AUTOSAR XML (schema 00048)
package /MICROSAR/vDem42_swc/DataTypes
  12 x impl type:
    Dem_DTCFormatType: compu {0=DEM_DTC_FORMAT_OBD, 1=DEM_DTC_FORMAT_UDS, 2=DEM_DTC_FORMAT_J1939}, range raw 0..255, implementation-data-type=uint8
    Dem_DTCOriginType:
      compu {1=DEM_DTC_ORIGIN_PRIMARY_MEMORY, 2=DEM_DTC_ORIGIN_MIRROR_MEMORY, 3=DEM_DTC_ORIGIN_PERMANENT_MEMORY, 4=DEM_DTC_ORIGIN_OBD_RELEVANT_MEMORY, 5=DEM_DTC_ORIGIN_SECONDARY_MEMORY, 5=DEM_DTC_ORIGIN_USERDEFINED_MEMORY_10, 5=DEM_DTC_ORIGIN_USERDEFINED_MEMORY_11, 5=DEM_DTC_ORIGIN_USERDEFINED_MEMORY_12, 5=DEM_DTC_ORIGIN_USERDEFINED_MEMORY_13, 5=DEM_DTC_ORIGIN_USERDEFINED_MEMORY_14, 5=DEM_DTC_ORIGIN_USERDEFINED_MEMORY_15, 5=DEM_DTC_ORIGIN_USERDEFINED_MEMORY_16, 5=DEM_DTC_ORIGIN_USERDEFINED_MEMORY_17, 5=DEM_DTC_ORIGIN_USERDEFINED_MEMORY_18, 5=DEM_DTC_ORIGIN_USERDEFINED_MEMORY_19, 5=DEM_DTC_ORIGIN_USERDEFINED_MEMORY_1A, 5=DEM_DTC_ORIGIN_USERDEFINED_MEMORY_1B, 5=DEM_DTC_ORIGIN_USERDEFINED_MEMORY_1C, 5=DEM_DTC_ORIGIN_USERDEFINED_MEMORY_1D, 5=DEM_DTC_ORIGIN_USERDEFINED_MEMORY_1E, 5=DEM_DTC_ORIGIN_USERDEFINED_MEMORY_1F, 5=DEM_DTC_ORIGIN_USERDEFINED_MEMORY_20, 5=DEM_DTC_ORIGIN_USERDEFINED_MEMORY_21, 5=DEM_DTC_ORIGIN_USERDEFINED_MEMORY_22, 5=DEM_DTC_ORIGIN_USERDEFINED_MEMORY_23, 5=DEM_DTC_ORIGIN_USERDEFINED_MEMORY_24, 5=DEM_DTC_ORIGIN_USERDEFINED_MEMORY_25, 5=DEM_DTC_ORIGIN_USERDEFINED_MEMORY_26, 5=DEM_DTC_ORIGIN_USERDEFINED_MEMORY_27, 5=DEM_DTC_ORIGIN_USERDEFINED_MEMORY_28, 5=DEM_DTC_ORIGIN_USERDEFINED_MEMORY_29, 5=DEM_DTC_ORIGIN_USERDEFINED_MEMORY_2A, 5=DEM_DTC_ORIGIN_USERDEFINED_MEMORY_2B, 5=DEM_DTC_ORIGIN_USERDEFINED_MEMORY_2C, 5=DEM_DTC_ORIGIN_USERDEFINED_MEMORY_2D, 5=DEM_DTC_ORIGIN_USERDEFINED_MEMORY_2E, 5=DEM_DTC_ORIGIN_USERDEFINED_MEMORY_2F, 5=DEM_DTC_ORIGIN_USERDEFINED_MEMORY_30, 5=DEM_DTC_ORIGIN_USERDEFINED_MEMORY_31, 5=DEM_DTC_ORIGIN_USERDEFINED_MEMORY_32, 5=DEM_DTC_ORIGIN_USERDEFINED_MEMORY_33, 5=DEM_DTC_ORIGIN_USERDEFINED_MEMORY_34, 5=DEM_DTC_ORIGIN_USERDEFINED_MEMORY_35, 5=DEM_DTC_ORIGIN_USERDEFINED_MEMORY_36, 5=DEM_DTC_ORIGIN_USERDEFINED_MEMORY_37, 5=DEM_DTC_ORIGIN_USERDEFINED_MEMORY_38, 5=DEM_DTC_ORIGIN_USERDEFINED_MEMORY_39, 5=DEM_DTC_ORIGIN_USERDEFINED_MEMORY_3A, 5=DEM_DTC_ORIGIN_USERDEFINED_MEMORY_3B, 5=DEM_DTC_ORIGIN_USERDEFINED_MEMORY_3C, 5=DEM_DTC_ORIGIN_USERDEFINED_MEMORY_3D, 5=DEM_DTC_ORIGIN_USERDEFINED_MEMORY_3E, 5=DEM_DTC_ORIGIN_USERDEFINED_MEMORY_3F, 5=DEM_DTC_ORIGIN_USERDEFINED_MEMORY_40, 5=DEM_DTC_ORIGIN_USERDEFINED_MEMORY_41, 5=DEM_DTC_ORIGIN_USERDEFINED_MEMORY_42, 5=DEM_DTC_ORIGIN_USERDEFINED_MEMORY_43, 5=DEM_DTC_ORIGIN_USERDEFINED_MEMORY_44, 5=DEM_DTC_ORIGIN_USERDEFINED_MEMORY_45, 5=DEM_DTC_ORIGIN_USERDEFINED_MEMORY_46, 5=DEM_DTC_ORIGIN_USERDEFINED_MEMORY_47, 5=DEM_DTC_ORIGIN_USERDEFINED_MEMORY_48, 5=DEM_DTC_ORIGIN_USERDEFINED_MEMORY_49, 5=DEM_DTC_ORIGIN_USERDEFINED_MEMORY_4A, 5=DEM_DTC_ORIGIN_USERDEFINED_MEMORY_4B, 5=DEM_DTC_ORIGIN_USERDEFINED_MEMORY_4C, 5=DEM_DTC_ORIGIN_USERDEFINED_MEMORY_4D, 5=DEM_DTC_ORIGIN_USERDEFINED_MEMORY_4E, 5=DEM_DTC_ORIGIN_USERDEFINED_MEMORY_4F, 5=DEM_DTC_ORIGIN_USERDEFINED_MEMORY_50, 5=DEM_DTC_ORIGIN_USERDEFINED_MEMORY_51, 5=DEM_DTC_ORIGIN_USERDEFINED_MEMORY_52, 5=DEM_DTC_ORIGIN_USERDEFINED_MEMORY_53, 5=DEM_DTC_ORIGIN_USERDEFINED_MEMORY_54, 5=DEM_DTC_ORIGIN_USERDEFINED_MEMORY_55, 5=DEM_DTC_ORIGIN_USERDEFINED_MEMORY_56, 5=DEM_DTC_ORIGIN_USERDEFINED_MEMORY_57, 5=DEM_DTC_ORIGIN_USERDEFINED_MEMORY_58, 5=DEM_DTC_ORIGIN_USERDEFINED_MEMORY_59, 5=DEM_DTC_ORIGIN_USERDEFINED_MEMORY_5A, 5=DEM_DTC_ORIGIN_USERDEFINED_MEMORY_5B, 5=DEM_DTC_ORIGIN_USERDEFINED_MEMORY_5C, 5=DEM_DTC_ORIGIN_USERDEFINED_MEMORY_5D, 5=DEM_DTC_ORIGIN_USERDEFINED_MEMORY_5E, 5=DEM_DTC_ORIGIN_USERDEFINED_MEMORY_5F, 5=DEM_DTC_ORIGIN_USERDEFINED_MEMORY_60, 5=DEM_DTC_ORIGIN_USERDEFINED_MEMORY_61, 5=DEM_DTC_ORIGIN_USERDEFINED_MEMORY_62, 5=DEM_DTC_ORIGIN_USERDEFINED_MEMORY_63, 5=DEM_DTC_ORIGIN_USERDEFINED_MEMORY_64, 5=DEM_DTC_ORIGIN_USERDEFINED_MEMORY_65, 5=DEM_DTC_ORIGIN_USERDEFINED_MEMORY_66, 5=DEM_DTC_ORIGIN_USERDEFINED_MEMORY_67, 5=DEM_DTC_ORIGIN_USERDEFINED_MEMORY_68, 5=DEM_DTC_ORIGIN_USERDEFINED_MEMORY_69, 5=DEM_DTC_ORIGIN_USERDEFINED_MEMORY_6A, 5=DEM_DTC_ORIGIN_USERDEFINED_MEMORY_6B, 5=DEM_DTC_ORIGIN_USERDEFINED_MEMORY_6C, 5=DEM_DTC_ORIGIN_USERDEFINED_MEMORY_6D, 5=DEM_DTC_ORIGIN_USERDEFINED_MEMORY_6E, 5=DEM_DTC_ORIGIN_USERDEFINED_MEMORY_6F, 5=DEM_DTC_ORIGIN_USERDEFINED_MEMORY_70, 5=DEM_DTC_ORIGIN_USERDEFINED_MEMORY_71, 5=DEM_DTC_ORIGIN_USERDEFINED_MEMORY_72, 5=DEM_DTC_ORIGIN_USERDEFINED_MEMORY_73, 5=DEM_DTC_ORIGIN_USERDEFINED_MEMORY_74, 5=DEM_DTC_ORIGIN_USERDEFINED_MEMORY_75, 5=DEM_DTC_ORIGIN_USERDEFINED_MEMORY_76, 5=DEM_DTC_ORIGIN_USERDEFINED_MEMORY_77, 5=DEM_DTC_ORIGIN_USERDEFINED_MEMORY_78, 5=DEM_DTC_ORIGIN_USERDEFINED_MEMORY_79, 5=DEM_DTC_ORIGIN_USERDEFINED_MEMORY_7A, 5=DEM_DTC_ORIGIN_USERDEFINED_MEMORY_7B, 5=DEM_DTC_ORIGIN_USERDEFINED_MEMORY_7C, 5=DEM_DTC_ORIGIN_USERDEFINED_MEMORY_7D, 5=DEM_DTC_ORIGIN_USERDEFINED_MEMORY_7E, 5=DEM_DTC_ORIGIN_USERDEFINED_MEMORY_7F, 5=DEM_DTC_ORIGIN_USERDEFINED_MEMORY_80, 5=DEM_DTC_ORIGIN_USERDEFINED_MEMORY_81, 5=DEM_DTC_ORIGIN_USERDEFINED_MEMORY_82, 5=DEM_DTC_ORIGIN_USERDEFINED_MEMORY_83, 5=DEM_DTC_ORIGIN_USERDEFINED_MEMORY_84, 5=DEM_DTC_ORIGIN_USERDEFINED_MEMORY_85, 5=DEM_DTC_ORIGIN_USERDEFINED_MEMORY_86, 5=DEM_DTC_ORIGIN_USERDEFINED_MEMORY_87, 5=DEM_DTC_ORIGIN_USERDEFINED_MEMORY_88, 5=DEM_DTC_ORIGIN_USERDEFINED_MEMORY_89, 5=DEM_DTC_ORIGIN_USERDEFINED_MEMORY_8A, 5=DEM_DTC_ORIGIN_USERDEFINED_MEMORY_8B, 5=DEM_DTC_ORIGIN_USERDEFINED_MEMORY_8C, 5=DEM_DTC_ORIGIN_USERDEFINED_MEMORY_8D, 5=DEM_DTC_ORIGIN_USERDEFINED_MEMORY_8E, 5=DEM_DTC_ORIGIN_USERDEFINED_MEMORY_8F, 5=DEM_DTC_ORIGIN_USERDEFINED_MEMORY_90, 5=DEM_DTC_ORIGIN_USERDEFINED_MEMORY_91, 5=DEM_DTC_ORIGIN_USERDEFINED_MEMORY_92, 5=DEM_DTC_ORIGIN_USERDEFINED_MEMORY_93, 5=DEM_DTC_ORIGIN_USERDEFINED_MEMORY_94, 5=DEM_DTC_ORIGIN_USERDEFINED_MEMORY_95, 5=DEM_DTC_ORIGIN_USERDEFINED_MEMORY_96, 5=DEM_DTC_ORIGIN_USERDEFINED_MEMORY_97, 5=DEM_DTC_ORIGIN_USERDEFINED_MEMORY_98, 5=DEM_DTC_ORIGIN_USERDEFINED_MEMORY_99, 5=DEM_DTC_ORIGIN_USERDEFINED_MEMORY_9A, 5=DEM_DTC_ORIGIN_USERDEFINED_MEMORY_9B, 5=DEM_DTC_ORIGIN_USERDEFINED_MEMORY_9C, 5=DEM_DTC_ORIGIN_USERDEFINED_MEMORY_9D, 5=DEM_DTC_ORIGIN_USERDEFINED_MEMORY_9E, 5=DEM_DTC_ORIGIN_USERDEFINED_MEMORY_9F, 5=DEM_DTC_ORIGIN_USERDEFINED_MEMORY_A0, 5=DEM_DTC_ORIGIN_USERDEFINED_MEMORY_A1, 5=DEM_DTC_ORIGIN_USERDEFINED_MEMORY_A2, 5=DEM_DTC_ORIGIN_USERDEFINED_MEMORY_A3, 5=DEM_DTC_ORIGIN_USERDEFINED_MEMORY_A4, 5=DEM_DTC_ORIGIN_USERDEFINED_MEMORY_A5, 5=DEM_DTC_ORIGIN_USERDEFINED_MEMORY_A6, 5=DEM_DTC_ORIGIN_USERDEFINED_MEMORY_A7, 5=DEM_DTC_ORIGIN_USERDEFINED_MEMORY_A8, 5=DEM_DTC_ORIGIN_USERDEFINED_MEMORY_A9, 5=DEM_DTC_ORIGIN_USERDEFINED_MEMORY_AA, 5=DEM_DTC_ORIGIN_USERDEFINED_MEMORY_AB, 5=DEM_DTC_ORIGIN_USERDEFINED_MEMORY_AC, 5=DEM_DTC_ORIGIN_USERDEFINED_MEMORY_AD, 5=DEM_DTC_ORIGIN_USERDEFINED_MEMORY_AE, 5=DEM_DTC_ORIGIN_USERDEFINED_MEMORY_AF, 5=DEM_DTC_ORIGIN_USERDEFINED_MEMORY_B0, 5=DEM_DTC_ORIGIN_USERDEFINED_MEMORY_B1, 5=DEM_DTC_ORIGIN_USERDEFINED_MEMORY_B2, 5=DEM_DTC_ORIGIN_USERDEFINED_MEMORY_B3, 5=DEM_DTC_ORIGIN_USERDEFINED_MEMORY_B4, 5=DEM_DTC_ORIGIN_USERDEFINED_MEMORY_B5, 5=DEM_DTC_ORIGIN_USERDEFINED_MEMORY_B6, 5=DEM_DTC_ORIGIN_USERDEFINED_MEMORY_B7, 5=DEM_DTC_ORIGIN_USERDEFINED_MEMORY_B8, 5=DEM_DTC_ORIGIN_USERDEFINED_MEMORY_B9, 5=DEM_DTC_ORIGIN_USERDEFINED_MEMORY_BA, 5=DEM_DTC_ORIGIN_USERDEFINED_MEMORY_BB, 5=DEM_DTC_ORIGIN_USERDEFINED_MEMORY_BC, 5=DEM_DTC_ORIGIN_USERDEFINED_MEMORY_BD, 5=DEM_DTC_ORIGIN_USERDEFINED_MEMORY_BE, 5=DEM_DTC_ORIGIN_USERDEFINED_MEMORY_BF, 5=DEM_DTC_ORIGIN_USERDEFINED_MEMORY_C0, 5=DEM_DTC_ORIGIN_USERDEFINED_MEMORY_C1, 5=DEM_DTC_ORIGIN_USERDEFINED_MEMORY_C2, 5=DEM_DTC_ORIGIN_USERDEFINED_MEMORY_C3, 5=DEM_DTC_ORIGIN_USERDEFINED_MEMORY_C4, 5=DEM_DTC_ORIGIN_USERDEFINED_MEMORY_C5, 5=DEM_DTC_ORIGIN_USERDEFINED_MEMORY_C6, 5=DEM_DTC_ORIGIN_USERDEFINED_MEMORY_C7, 5=DEM_DTC_ORIGIN_USERDEFINED_MEMORY_C8, 5=DEM_DTC_ORIGIN_USERDEFINED_MEMORY_C9, 5=DEM_DTC_ORIGIN_USERDEFINED_MEMORY_CA, 5=DEM_DTC_ORIGIN_USERDEFINED_MEMORY_CB, 5=DEM_DTC_ORIGIN_USERDEFINED_MEMORY_CC, 5=DEM_DTC_ORIGIN_USERDEFINED_MEMORY_CD, 5=DEM_DTC_ORIGIN_USERDEFINED_MEMORY_CE, 5=DEM_DTC_ORIGIN_USERDEFINED_MEMORY_CF, 5=DEM_DTC_ORIGIN_USERDEFINED_MEMORY_D0, 5=DEM_DTC_ORIGIN_USERDEFINED_MEMORY_D1, 5=DEM_DTC_ORIGIN_USERDEFINED_MEMORY_D2, 5=DEM_DTC_ORIGIN_USERDEFINED_MEMORY_D3, 5=DEM_DTC_ORIGIN_USERDEFINED_MEMORY_D4, 5=DEM_DTC_ORIGIN_USERDEFINED_MEMORY_D5, 5=DEM_DTC_ORIGIN_USERDEFINED_MEMORY_D6, 5=DEM_DTC_ORIGIN_USERDEFINED_MEMORY_D7, 5=DEM_DTC_ORIGIN_USERDEFINED_MEMORY_D8, 5=DEM_DTC_ORIGIN_USERDEFINED_MEMORY_D9, 5=DEM_DTC_ORIGIN_USERDEFINED_MEMORY_DA, 5=DEM_DTC_ORIGIN_USERDEFINED_MEMORY_DB, 5=DEM_DTC_ORIGIN_USERDEFINED_MEMORY_DC, 5=DEM_DTC_ORIGIN_USERDEFINED_MEMORY_DD, 5=DEM_DTC_ORIGIN_USERDEFINED_MEMORY_DE, 5=DEM_DTC_ORIGIN_USERDEFINED_MEMORY_DF, 5=DEM_DTC_ORIGIN_USERDEFINED_MEMORY_E0, 5=DEM_DTC_ORIGIN_USERDEFINED_MEMORY_E1, 5=DEM_DTC_ORIGIN_USERDEFINED_MEMORY_E2, 5=DEM_DTC_ORIGIN_USERDEFINED_MEMORY_E3, 5=DEM_DTC_ORIGIN_USERDEFINED_MEMORY_E4, 5=DEM_DTC_ORIGIN_USERDEFINED_MEMORY_E5, 5=DEM_DTC_ORIGIN_USERDEFINED_MEMORY_E6, 5=DEM_DTC_ORIGIN_USERDEFINED_MEMORY_E7, 5=DEM_DTC_ORIGIN_USERDEFINED_MEMORY_E8, 5=DEM_DTC_ORIGIN_USERDEFINED_MEMORY_E9, 5=DEM_DTC_ORIGIN_USERDEFINED_MEMORY_EA, 5=DEM_DTC_ORIGIN_USERDEFINED_MEMORY_EB, 5=DEM_DTC_ORIGIN_USERDEFINED_MEMORY_EC, 5=DEM_DTC_ORIGIN_USERDEFINED_MEMORY_ED, 5=DEM_DTC_ORIGIN_USERDEFINED_MEMORY_EE, 5=DEM_DTC_ORIGIN_USERDEFINED_MEMORY_EF, 5=DEM_DTC_ORIGIN_USERDEFINED_MEMORY_F0, 5=DEM_DTC_ORIGIN_USERDEFINED_MEMORY_F1, 5=DEM_DTC_ORIGIN_USERDEFINED_MEMORY_F2, 5=DEM_DTC_ORIGIN_USERDEFINED_MEMORY_F3, 5=DEM_DTC_ORIGIN_USERDEFINED_MEMORY_F4, 5=DEM_DTC_ORIGIN_USERDEFINED_MEMORY_F5, 5=DEM_DTC_ORIGIN_USERDEFINED_MEMORY_F6, 5=DEM_DTC_ORIGIN_USERDEFINED_MEMORY_F7, 5=DEM_DTC_ORIGIN_USERDEFINED_MEMORY_F8, 5=DEM_DTC_ORIGIN_USERDEFINED_MEMORY_F9, 5=DEM_DTC_ORIGIN_USERDEFINED_MEMORY_FA, 5=DEM_DTC_ORIGIN_USERDEFINED_MEMORY_FB, 5=DEM_DTC_ORIGIN_USERDEFINED_MEMORY_FC, 5=DEM_DTC_ORIGIN_USERDEFINED_MEMORY_FD, 5=DEM_DTC_ORIGIN_USERDEFINED_MEMORY_FE, 5=DEM_DTC_ORIGIN_USERDEFINED_MEMORY_FF}
      range raw 0..65535
      implementation-data-type=uint16
    Dem_UdsStatusByteType: compu {mask 1: 1=DEM_UDS_STATUS_TF, mask 2: 2=DEM_UDS_STATUS_TFTOC, mask 4: 4=DEM_UDS_STATUS_PDTC, mask 8: 8=DEM_UDS_STATUS_CDTC, mask 16: 16=DEM_UDS_STATUS_TNCSLC, mask 32: 32=DEM_UDS_STATUS_TFSLC, mask 64: 64=DEM_UDS_STATUS_TNCTOC, mask 128: 128=DEM_UDS_STATUS_WIR}, range raw 0..255, implementation-data-type=uint8
    Dem_EventIdType: range raw 1..65535, implementation-data-type=uint16
    Dem_MaxDataValueType: category=ARRAY, sw-calibration-access=READ-ONLY
      element Dem_MaxDataValueTypeElement: array-size=1, array-size-semantics=FIXED-SIZE, implementation-data-type=uint8
    Dem_DebouncingStateType: compu {mask 1: 1=DEM_TEMPORARILY_DEFECTIVE, mask 2: 2=DEM_FINALLY_DEFECTIVE, mask 4: 4=DEM_TEMPORARILY_HEALED, mask 8: 8=DEM_TEST_COMPLETE, mask 16: 16=DEM_DTR_UPDATE}, range raw 0..255, implementation-data-type=uint8
    VDem42_DTCFormatType: compu {0=VDEM42_DTC_FORMAT_OBD, 1=VDEM42_DTC_FORMAT_UDS, 2=VDEM42_DTC_FORMAT_J1939}, range raw 0..255, implementation-data-type=uint8
    VDem42_DTCOriginType:
      compu {1=VDEM42_DTC_ORIGIN_PRIMARY_MEMORY, 2=VDEM42_DTC_ORIGIN_MIRROR_MEMORY, 3=VDEM42_DTC_ORIGIN_PERMANENT_MEMORY, 4=VDEM42_DTC_ORIGIN_OBD_RELEVANT_MEMORY, 5=VDEM42_DTC_ORIGIN_SECONDARY_MEMORY, 5=VDEM42_DTC_ORIGIN_USERDEFINED_MEMORY_10, 5=VDEM42_DTC_ORIGIN_USERDEFINED_MEMORY_11, 5=VDEM42_DTC_ORIGIN_USERDEFINED_MEMORY_12, 5=VDEM42_DTC_ORIGIN_USERDEFINED_MEMORY_13, 5=VDEM42_DTC_ORIGIN_USERDEFINED_MEMORY_14, 5=VDEM42_DTC_ORIGIN_USERDEFINED_MEMORY_15, 5=VDEM42_DTC_ORIGIN_USERDEFINED_MEMORY_16, 5=VDEM42_DTC_ORIGIN_USERDEFINED_MEMORY_17, 5=VDEM42_DTC_ORIGIN_USERDEFINED_MEMORY_18, 5=VDEM42_DTC_ORIGIN_USERDEFINED_MEMORY_19, 5=VDEM42_DTC_ORIGIN_USERDEFINED_MEMORY_1A, 5=VDEM42_DTC_ORIGIN_USERDEFINED_MEMORY_1B, 5=VDEM42_DTC_ORIGIN_USERDEFINED_MEMORY_1C, 5=VDEM42_DTC_ORIGIN_USERDEFINED_MEMORY_1D, 5=VDEM42_DTC_ORIGIN_USERDEFINED_MEMORY_1E, 5=VDEM42_DTC_ORIGIN_USERDEFINED_MEMORY_1F, 5=VDEM42_DTC_ORIGIN_USERDEFINED_MEMORY_20, 5=VDEM42_DTC_ORIGIN_USERDEFINED_MEMORY_21, 5=VDEM42_DTC_ORIGIN_USERDEFINED_MEMORY_22, 5=VDEM42_DTC_ORIGIN_USERDEFINED_MEMORY_23, 5=VDEM42_DTC_ORIGIN_USERDEFINED_MEMORY_24, 5=VDEM42_DTC_ORIGIN_USERDEFINED_MEMORY_25, 5=VDEM42_DTC_ORIGIN_USERDEFINED_MEMORY_26, 5=VDEM42_DTC_ORIGIN_USERDEFINED_MEMORY_27, 5=VDEM42_DTC_ORIGIN_USERDEFINED_MEMORY_28, 5=VDEM42_DTC_ORIGIN_USERDEFINED_MEMORY_29, 5=VDEM42_DTC_ORIGIN_USERDEFINED_MEMORY_2A, 5=VDEM42_DTC_ORIGIN_USERDEFINED_MEMORY_2B, 5=VDEM42_DTC_ORIGIN_USERDEFINED_MEMORY_2C, 5=VDEM42_DTC_ORIGIN_USERDEFINED_MEMORY_2D, 5=VDEM42_DTC_ORIGIN_USERDEFINED_MEMORY_2E, 5=VDEM42_DTC_ORIGIN_USERDEFINED_MEMORY_2F, 5=VDEM42_DTC_ORIGIN_USERDEFINED_MEMORY_30, 5=VDEM42_DTC_ORIGIN_USERDEFINED_MEMORY_31, 5=VDEM42_DTC_ORIGIN_USERDEFINED_MEMORY_32, 5=VDEM42_DTC_ORIGIN_USERDEFINED_MEMORY_33, 5=VDEM42_DTC_ORIGIN_USERDEFINED_MEMORY_34, 5=VDEM42_DTC_ORIGIN_USERDEFINED_MEMORY_35, 5=VDEM42_DTC_ORIGIN_USERDEFINED_MEMORY_36, 5=VDEM42_DTC_ORIGIN_USERDEFINED_MEMORY_37, 5=VDEM42_DTC_ORIGIN_USERDEFINED_MEMORY_38, 5=VDEM42_DTC_ORIGIN_USERDEFINED_MEMORY_39, 5=VDEM42_DTC_ORIGIN_USERDEFINED_MEMORY_3A, 5=VDEM42_DTC_ORIGIN_USERDEFINED_MEMORY_3B, 5=VDEM42_DTC_ORIGIN_USERDEFINED_MEMORY_3C, 5=VDEM42_DTC_ORIGIN_USERDEFINED_MEMORY_3D, 5=VDEM42_DTC_ORIGIN_USERDEFINED_MEMORY_3E, 5=VDEM42_DTC_ORIGIN_USERDEFINED_MEMORY_3F, 5=VDEM42_DTC_ORIGIN_USERDEFINED_MEMORY_40, 5=VDEM42_DTC_ORIGIN_USERDEFINED_MEMORY_41, 5=VDEM42_DTC_ORIGIN_USERDEFINED_MEMORY_42, 5=VDEM42_DTC_ORIGIN_USERDEFINED_MEMORY_43, 5=VDEM42_DTC_ORIGIN_USERDEFINED_MEMORY_44, 5=VDEM42_DTC_ORIGIN_USERDEFINED_MEMORY_45, 5=VDEM42_DTC_ORIGIN_USERDEFINED_MEMORY_46, 5=VDEM42_DTC_ORIGIN_USERDEFINED_MEMORY_47, 5=VDEM42_DTC_ORIGIN_USERDEFINED_MEMORY_48, 5=VDEM42_DTC_ORIGIN_USERDEFINED_MEMORY_49, 5=VDEM42_DTC_ORIGIN_USERDEFINED_MEMORY_4A, 5=VDEM42_DTC_ORIGIN_USERDEFINED_MEMORY_4B, 5=VDEM42_DTC_ORIGIN_USERDEFINED_MEMORY_4C, 5=VDEM42_DTC_ORIGIN_USERDEFINED_MEMORY_4D, 5=VDEM42_DTC_ORIGIN_USERDEFINED_MEMORY_4E, 5=VDEM42_DTC_ORIGIN_USERDEFINED_MEMORY_4F, 5=VDEM42_DTC_ORIGIN_USERDEFINED_MEMORY_50, 5=VDEM42_DTC_ORIGIN_USERDEFINED_MEMORY_51, 5=VDEM42_DTC_ORIGIN_USERDEFINED_MEMORY_52, 5=VDEM42_DTC_ORIGIN_USERDEFINED_MEMORY_53, 5=VDEM42_DTC_ORIGIN_USERDEFINED_MEMORY_54, 5=VDEM42_DTC_ORIGIN_USERDEFINED_MEMORY_55, 5=VDEM42_DTC_ORIGIN_USERDEFINED_MEMORY_56, 5=VDEM42_DTC_ORIGIN_USERDEFINED_MEMORY_57, 5=VDEM42_DTC_ORIGIN_USERDEFINED_MEMORY_58, 5=VDEM42_DTC_ORIGIN_USERDEFINED_MEMORY_59, 5=VDEM42_DTC_ORIGIN_USERDEFINED_MEMORY_5A, 5=VDEM42_DTC_ORIGIN_USERDEFINED_MEMORY_5B, 5=VDEM42_DTC_ORIGIN_USERDEFINED_MEMORY_5C, 5=VDEM42_DTC_ORIGIN_USERDEFINED_MEMORY_5D, 5=VDEM42_DTC_ORIGIN_USERDEFINED_MEMORY_5E, 5=VDEM42_DTC_ORIGIN_USERDEFINED_MEMORY_5F, 5=VDEM42_DTC_ORIGIN_USERDEFINED_MEMORY_60, 5=VDEM42_DTC_ORIGIN_USERDEFINED_MEMORY_61, 5=VDEM42_DTC_ORIGIN_USERDEFINED_MEMORY_62, 5=VDEM42_DTC_ORIGIN_USERDEFINED_MEMORY_63, 5=VDEM42_DTC_ORIGIN_USERDEFINED_MEMORY_64, 5=VDEM42_DTC_ORIGIN_USERDEFINED_MEMORY_65, 5=VDEM42_DTC_ORIGIN_USERDEFINED_MEMORY_66, 5=VDEM42_DTC_ORIGIN_USERDEFINED_MEMORY_67, 5=VDEM42_DTC_ORIGIN_USERDEFINED_MEMORY_68, 5=VDEM42_DTC_ORIGIN_USERDEFINED_MEMORY_69, 5=VDEM42_DTC_ORIGIN_USERDEFINED_MEMORY_6A, 5=VDEM42_DTC_ORIGIN_USERDEFINED_MEMORY_6B, 5=VDEM42_DTC_ORIGIN_USERDEFINED_MEMORY_6C, 5=VDEM42_DTC_ORIGIN_USERDEFINED_MEMORY_6D, 5=VDEM42_DTC_ORIGIN_USERDEFINED_MEMORY_6E, 5=VDEM42_DTC_ORIGIN_USERDEFINED_MEMORY_6F, 5=VDEM42_DTC_ORIGIN_USERDEFINED_MEMORY_70, 5=VDEM42_DTC_ORIGIN_USERDEFINED_MEMORY_71, 5=VDEM42_DTC_ORIGIN_USERDEFINED_MEMORY_72, 5=VDEM42_DTC_ORIGIN_USERDEFINED_MEMORY_73, 5=VDEM42_DTC_ORIGIN_USERDEFINED_MEMORY_74, 5=VDEM42_DTC_ORIGIN_USERDEFINED_MEMORY_75, 5=VDEM42_DTC_ORIGIN_USERDEFINED_MEMORY_76, 5=VDEM42_DTC_ORIGIN_USERDEFINED_MEMORY_77, 5=VDEM42_DTC_ORIGIN_USERDEFINED_MEMORY_78, 5=VDEM42_DTC_ORIGIN_USERDEFINED_MEMORY_79, 5=VDEM42_DTC_ORIGIN_USERDEFINED_MEMORY_7A, 5=VDEM42_DTC_ORIGIN_USERDEFINED_MEMORY_7B, 5=VDEM42_DTC_ORIGIN_USERDEFINED_MEMORY_7C, 5=VDEM42_DTC_ORIGIN_USERDEFINED_MEMORY_7D, 5=VDEM42_DTC_ORIGIN_USERDEFINED_MEMORY_7E, 5=VDEM42_DTC_ORIGIN_USERDEFINED_MEMORY_7F, 5=VDEM42_DTC_ORIGIN_USERDEFINED_MEMORY_80, 5=VDEM42_DTC_ORIGIN_USERDEFINED_MEMORY_81, 5=VDEM42_DTC_ORIGIN_USERDEFINED_MEMORY_82, 5=VDEM42_DTC_ORIGIN_USERDEFINED_MEMORY_83, 5=VDEM42_DTC_ORIGIN_USERDEFINED_MEMORY_84, 5=VDEM42_DTC_ORIGIN_USERDEFINED_MEMORY_85, 5=VDEM42_DTC_ORIGIN_USERDEFINED_MEMORY_86, 5=VDEM42_DTC_ORIGIN_USERDEFINED_MEMORY_87, 5=VDEM42_DTC_ORIGIN_USERDEFINED_MEMORY_88, 5=VDEM42_DTC_ORIGIN_USERDEFINED_MEMORY_89, 5=VDEM42_DTC_ORIGIN_USERDEFINED_MEMORY_8A, 5=VDEM42_DTC_ORIGIN_USERDEFINED_MEMORY_8B, 5=VDEM42_DTC_ORIGIN_USERDEFINED_MEMORY_8C, 5=VDEM42_DTC_ORIGIN_USERDEFINED_MEMORY_8D, 5=VDEM42_DTC_ORIGIN_USERDEFINED_MEMORY_8E, 5=VDEM42_DTC_ORIGIN_USERDEFINED_MEMORY_8F, 5=VDEM42_DTC_ORIGIN_USERDEFINED_MEMORY_90, 5=VDEM42_DTC_ORIGIN_USERDEFINED_MEMORY_91, 5=VDEM42_DTC_ORIGIN_USERDEFINED_MEMORY_92, 5=VDEM42_DTC_ORIGIN_USERDEFINED_MEMORY_93, 5=VDEM42_DTC_ORIGIN_USERDEFINED_MEMORY_94, 5=VDEM42_DTC_ORIGIN_USERDEFINED_MEMORY_95, 5=VDEM42_DTC_ORIGIN_USERDEFINED_MEMORY_96, 5=VDEM42_DTC_ORIGIN_USERDEFINED_MEMORY_97, 5=VDEM42_DTC_ORIGIN_USERDEFINED_MEMORY_98, 5=VDEM42_DTC_ORIGIN_USERDEFINED_MEMORY_99, 5=VDEM42_DTC_ORIGIN_USERDEFINED_MEMORY_9A, 5=VDEM42_DTC_ORIGIN_USERDEFINED_MEMORY_9B, 5=VDEM42_DTC_ORIGIN_USERDEFINED_MEMORY_9C, 5=VDEM42_DTC_ORIGIN_USERDEFINED_MEMORY_9D, 5=VDEM42_DTC_ORIGIN_USERDEFINED_MEMORY_9E, 5=VDEM42_DTC_ORIGIN_USERDEFINED_MEMORY_9F, 5=VDEM42_DTC_ORIGIN_USERDEFINED_MEMORY_A0, 5=VDEM42_DTC_ORIGIN_USERDEFINED_MEMORY_A1, 5=VDEM42_DTC_ORIGIN_USERDEFINED_MEMORY_A2, 5=VDEM42_DTC_ORIGIN_USERDEFINED_MEMORY_A3, 5=VDEM42_DTC_ORIGIN_USERDEFINED_MEMORY_A4, 5=VDEM42_DTC_ORIGIN_USERDEFINED_MEMORY_A5, 5=VDEM42_DTC_ORIGIN_USERDEFINED_MEMORY_A6, 5=VDEM42_DTC_ORIGIN_USERDEFINED_MEMORY_A7, 5=VDEM42_DTC_ORIGIN_USERDEFINED_MEMORY_A8, 5=VDEM42_DTC_ORIGIN_USERDEFINED_MEMORY_A9, 5=VDEM42_DTC_ORIGIN_USERDEFINED_MEMORY_AA, 5=VDEM42_DTC_ORIGIN_USERDEFINED_MEMORY_AB, 5=VDEM42_DTC_ORIGIN_USERDEFINED_MEMORY_AC, 5=VDEM42_DTC_ORIGIN_USERDEFINED_MEMORY_AD, 5=VDEM42_DTC_ORIGIN_USERDEFINED_MEMORY_AE, 5=VDEM42_DTC_ORIGIN_USERDEFINED_MEMORY_AF, 5=VDEM42_DTC_ORIGIN_USERDEFINED_MEMORY_B0, 5=VDEM42_DTC_ORIGIN_USERDEFINED_MEMORY_B1, 5=VDEM42_DTC_ORIGIN_USERDEFINED_MEMORY_B2, 5=VDEM42_DTC_ORIGIN_USERDEFINED_MEMORY_B3, 5=VDEM42_DTC_ORIGIN_USERDEFINED_MEMORY_B4, 5=VDEM42_DTC_ORIGIN_USERDEFINED_MEMORY_B5, 5=VDEM42_DTC_ORIGIN_USERDEFINED_MEMORY_B6, 5=VDEM42_DTC_ORIGIN_USERDEFINED_MEMORY_B7, 5=VDEM42_DTC_ORIGIN_USERDEFINED_MEMORY_B8, 5=VDEM42_DTC_ORIGIN_USERDEFINED_MEMORY_B9, 5=VDEM42_DTC_ORIGIN_USERDEFINED_MEMORY_BA, 5=VDEM42_DTC_ORIGIN_USERDEFINED_MEMORY_BB, 5=VDEM42_DTC_ORIGIN_USERDEFINED_MEMORY_BC, 5=VDEM42_DTC_ORIGIN_USERDEFINED_MEMORY_BD, 5=VDEM42_DTC_ORIGIN_USERDEFINED_MEMORY_BE, 5=VDEM42_DTC_ORIGIN_USERDEFINED_MEMORY_BF, 5=VDEM42_DTC_ORIGIN_USERDEFINED_MEMORY_C0, 5=VDEM42_DTC_ORIGIN_USERDEFINED_MEMORY_C1, 5=VDEM42_DTC_ORIGIN_USERDEFINED_MEMORY_C2, 5=VDEM42_DTC_ORIGIN_USERDEFINED_MEMORY_C3, 5=VDEM42_DTC_ORIGIN_USERDEFINED_MEMORY_C4, 5=VDEM42_DTC_ORIGIN_USERDEFINED_MEMORY_C5, 5=VDEM42_DTC_ORIGIN_USERDEFINED_MEMORY_C6, 5=VDEM42_DTC_ORIGIN_USERDEFINED_MEMORY_C7, 5=VDEM42_DTC_ORIGIN_USERDEFINED_MEMORY_C8, 5=VDEM42_DTC_ORIGIN_USERDEFINED_MEMORY_C9, 5=VDEM42_DTC_ORIGIN_USERDEFINED_MEMORY_CA, 5=VDEM42_DTC_ORIGIN_USERDEFINED_MEMORY_CB, 5=VDEM42_DTC_ORIGIN_USERDEFINED_MEMORY_CC, 5=VDEM42_DTC_ORIGIN_USERDEFINED_MEMORY_CD, 5=VDEM42_DTC_ORIGIN_USERDEFINED_MEMORY_CE, 5=VDEM42_DTC_ORIGIN_USERDEFINED_MEMORY_CF, 5=VDEM42_DTC_ORIGIN_USERDEFINED_MEMORY_D0, 5=VDEM42_DTC_ORIGIN_USERDEFINED_MEMORY_D1, 5=VDEM42_DTC_ORIGIN_USERDEFINED_MEMORY_D2, 5=VDEM42_DTC_ORIGIN_USERDEFINED_MEMORY_D3, 5=VDEM42_DTC_ORIGIN_USERDEFINED_MEMORY_D4, 5=VDEM42_DTC_ORIGIN_USERDEFINED_MEMORY_D5, 5=VDEM42_DTC_ORIGIN_USERDEFINED_MEMORY_D6, 5=VDEM42_DTC_ORIGIN_USERDEFINED_MEMORY_D7, 5=VDEM42_DTC_ORIGIN_USERDEFINED_MEMORY_D8, 5=VDEM42_DTC_ORIGIN_USERDEFINED_MEMORY_D9, 5=VDEM42_DTC_ORIGIN_USERDEFINED_MEMORY_DA, 5=VDEM42_DTC_ORIGIN_USERDEFINED_MEMORY_DB, 5=VDEM42_DTC_ORIGIN_USERDEFINED_MEMORY_DC, 5=VDEM42_DTC_ORIGIN_USERDEFINED_MEMORY_DD, 5=VDEM42_DTC_ORIGIN_USERDEFINED_MEMORY_DE, 5=VDEM42_DTC_ORIGIN_USERDEFINED_MEMORY_DF, 5=VDEM42_DTC_ORIGIN_USERDEFINED_MEMORY_E0, 5=VDEM42_DTC_ORIGIN_USERDEFINED_MEMORY_E1, 5=VDEM42_DTC_ORIGIN_USERDEFINED_MEMORY_E2, 5=VDEM42_DTC_ORIGIN_USERDEFINED_MEMORY_E3, 5=VDEM42_DTC_ORIGIN_USERDEFINED_MEMORY_E4, 5=VDEM42_DTC_ORIGIN_USERDEFINED_MEMORY_E5, 5=VDEM42_DTC_ORIGIN_USERDEFINED_MEMORY_E6, 5=VDEM42_DTC_ORIGIN_USERDEFINED_MEMORY_E7, 5=VDEM42_DTC_ORIGIN_USERDEFINED_MEMORY_E8, 5=VDEM42_DTC_ORIGIN_USERDEFINED_MEMORY_E9, 5=VDEM42_DTC_ORIGIN_USERDEFINED_MEMORY_EA, 5=VDEM42_DTC_ORIGIN_USERDEFINED_MEMORY_EB, 5=VDEM42_DTC_ORIGIN_USERDEFINED_MEMORY_EC, 5=VDEM42_DTC_ORIGIN_USERDEFINED_MEMORY_ED, 5=VDEM42_DTC_ORIGIN_USERDEFINED_MEMORY_EE, 5=VDEM42_DTC_ORIGIN_USERDEFINED_MEMORY_EF, 5=VDEM42_DTC_ORIGIN_USERDEFINED_MEMORY_F0, 5=VDEM42_DTC_ORIGIN_USERDEFINED_MEMORY_F1, 5=VDEM42_DTC_ORIGIN_USERDEFINED_MEMORY_F2, 5=VDEM42_DTC_ORIGIN_USERDEFINED_MEMORY_F3, 5=VDEM42_DTC_ORIGIN_USERDEFINED_MEMORY_F4, 5=VDEM42_DTC_ORIGIN_USERDEFINED_MEMORY_F5, 5=VDEM42_DTC_ORIGIN_USERDEFINED_MEMORY_F6, 5=VDEM42_DTC_ORIGIN_USERDEFINED_MEMORY_F7, 5=VDEM42_DTC_ORIGIN_USERDEFINED_MEMORY_F8, 5=VDEM42_DTC_ORIGIN_USERDEFINED_MEMORY_F9, 5=VDEM42_DTC_ORIGIN_USERDEFINED_MEMORY_FA, 5=VDEM42_DTC_ORIGIN_USERDEFINED_MEMORY_FB, 5=VDEM42_DTC_ORIGIN_USERDEFINED_MEMORY_FC, 5=VDEM42_DTC_ORIGIN_USERDEFINED_MEMORY_FD, 5=VDEM42_DTC_ORIGIN_USERDEFINED_MEMORY_FE, 5=VDEM42_DTC_ORIGIN_USERDEFINED_MEMORY_FF}
      range raw 0..255
      implementation-data-type=uint8
    VDem42_UdsStatusByteType: compu {mask 1: 1=VDEM42_UDS_STATUS_TF, mask 2: 2=VDEM42_UDS_STATUS_TFTOC, mask 4: 4=VDEM42_UDS_STATUS_PDTC, mask 8: 8=VDEM42_UDS_STATUS_CDTC, mask 16: 16=VDEM42_UDS_STATUS_TNCSLC, mask 32: 32=VDEM42_UDS_STATUS_TFSLC, mask 64: 64=VDEM42_UDS_STATUS_TNCTOC, mask 128: 128=VDEM42_UDS_STATUS_WIR}, range raw 0..255, implementation-data-type=uint8
    VDem42_EventIdType: range raw 1..65535, implementation-data-type=uint16
    VDem42_MaxDataValueType: category=ARRAY, sw-calibration-access=READ-ONLY
      element VDem42_MaxDataValueTypeElement: array-size=1, array-size-semantics=FIXED-SIZE, implementation-data-type=uint8
    VDem42_DebouncingStateType: compu {mask 1: 1=VDEM42_TEMPORARILY_DEFECTIVE, mask 2: 2=VDEM42_FINALLY_DEFECTIVE, mask 4: 4=VDEM42_TEMPORARILY_HEALED, mask 8: 8=VDEM42_TEST_COMPLETE, mask 16: 16=VDEM42_DTR_UPDATE}, range raw 0..255, implementation-data-type=uint8
package /MICROSAR/vDem42_swc/Interfaces
  4 x client server interface, all with is-service=true, service-kind=VENDOR-SPECIFIC:
    CddIf
      operation ClearDTC: possible-error=[CddIf/DEM_CLEAR_FAILED, DEM_CLEAR_PENDING, CddIf/DEM_CLEAR_BUSY, CddIf/DEM_CLEAR_MEMORY_ERROR, DEM_CLEAR_WRONG_DTC, DEM_CLEAR_WRONG_DTCORIGIN]
        arg DTC: type=uint32, direction=IN
        arg DTCFormat: type=VDem42_DTCFormatType, direction=IN
        arg DTCOrigin: type=VDem42_DTCOriginType, direction=IN
      6 x error:
        DEM_CLEAR_FAILED: error-code=3
        DEM_CLEAR_PENDING: error-code=4
        DEM_CLEAR_BUSY: error-code=5
        DEM_CLEAR_MEMORY_ERROR: error-code=6
        DEM_CLEAR_WRONG_DTC: error-code=1
        DEM_CLEAR_WRONG_DTCORIGIN: error-code=2
    DTCSuppression422
      operation SetDTCSuppression: possible-error=DTCSuppression422/E_NOT_OK
        arg DTC: type=uint32, direction=IN
        arg DTCFormat: type=VDem42_DTCFormatType, direction=IN
        arg SuppressionStatus: type=boolean, direction=IN
      operation GetDTCSuppression: possible-error=DTCSuppression422/E_NOT_OK
        arg DTC: type=uint32, direction=IN
        arg DTCFormat: type=VDem42_DTCFormatType, direction=IN
        arg SuppressionStatus: type=boolean, direction=OUT
      error E_NOT_OK: error-code=1
    ClearDTC
      operation ClearDTC: possible-error=[ClearDTC/E_NOT_OK, ClearDTC/DEM_CLEAR_FAILED, ClearDTC/DEM_PENDING, ClearDTC/DEM_CLEAR_BUSY, ClearDTC/DEM_CLEAR_MEMORY_ERROR, ClearDTC/DEM_WRONG_DTC, ClearDTC/DEM_WRONG_DTCORIGIN]
      operation SelectDTC: possible-error=ClearDTC/E_NOT_OK
        arg DTC: type=uint32, direction=IN
        arg DTCFormat: type=Dem_DTCFormatType, direction=IN
        arg DTCOrigin: type=Dem_DTCOriginType, direction=IN
      7 x error:
        E_NOT_OK: error-code=1
        DEM_CLEAR_FAILED: error-code=7
        DEM_PENDING: error-code=4
        DEM_CLEAR_BUSY: error-code=5
        DEM_CLEAR_MEMORY_ERROR: error-code=6
        DEM_WRONG_DTC: error-code=8
        DEM_WRONG_DTCORIGIN: error-code=9
    DTCSuppression43
      operation SetDTCSuppression: possible-error=[DTCSuppression43/E_NOT_OK, DTCSuppression43/DEM_WRONG_DTC, DTCSuppression43/DEM_WRONG_DTCORIGIN, DTCSuppression43/DEM_PENDING]
        arg SuppressionStatus: type=boolean, direction=IN
      operation GetDTCSuppression: possible-error=[DTCSuppression43/E_NOT_OK, DTCSuppression43/DEM_WRONG_DTC, DTCSuppression43/DEM_WRONG_DTCORIGIN, DTCSuppression43/DEM_PENDING]
        arg SuppressionStatus: type=boolean, direction=OUT
      4 x error:
        E_NOT_OK: error-code=1
        DEM_WRONG_DTC: error-code=8
        DEM_WRONG_DTCORIGIN: error-code=9
        DEM_PENDING: error-code=4
package /MICROSAR/vDem42_swc/ComponentTypes
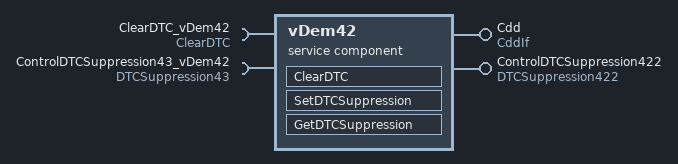
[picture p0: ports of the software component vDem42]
  service sw component type vDem42: category=SERVICE_COMPONENT
    provide port Cdd: provided-interface=CddIf
    provide port ControlDTCSuppression422: provided-interface=DTCSuppression422
    require port ClearDTC_vDem42: required-interface=ClearDTC
    require port ControlDTCSuppression43_vDem42: required-interface=DTCSuppression43
    behavior vDem42InternalBehavior: handle-termination-and-restart=NO-SUPPORT, included-data-type-set=data-type=[Dem_DTCFormatType, Dem_DTCOriginType, Dem_UdsStatusByteType, Dem_EventIdType, Dem_MaxDataValueType, Dem_DebouncingStateType, VDem42_DTCFormatType, VDem42_DTCOriginType, VDem42_UdsStatusByteType, VDem42_EventIdType, VDem42_MaxDataValueType, VDem42_DebouncingStateType]
      operation invoked event OpEventClearDTC_ClearDTC_Cdd: start-on-event=ClearDTC, operation=Cdd.ClearDTC
      operation invoked event OpEventSetDTCSuppression_SetDTCSuppression_ControlDTCSuppression422: start-on-event=SetDTCSuppression, operation=ControlDTCSuppression422.SetDTCSuppression
      operation invoked event OpEventGetDTCSuppression_GetDTCSuppression_ControlDTCSuppression422: start-on-event=GetDTCSuppression, operation=ControlDTCSuppression422.GetDTCSuppression
      port-api-options:
        enable-take-address=true, indirect-api=false, port=Cdd
        enable-take-address=true, indirect-api=false, port=ControlDTCSuppression422
        enable-take-address=true, indirect-api=false, port=ClearDTC_vDem42
        enable-take-address=true, indirect-api=false, port=ControlDTCSuppression43_vDem42
      runnable ClearDTC: can-be-invoked-concurrently=true, symbol=VDem42_ClearDTC
        sync call OpServerCallClearDTC_ClearDTC_ClearDTC_vDem42: operation=ClearDTC_vDem42.ClearDTC, timeout=0
        sync call OpServerCallClearDTC_SelectDTC_ClearDTC_vDem42: operation=ClearDTC_vDem42.SelectDTC, timeout=0
      runnable SetDTCSuppression: can-be-invoked-concurrently=true, symbol=VDem42_SetDTCSuppression
        sync call OpServerCallSetDTCSuppression_SelectDTC_ClearDTC_vDem42: operation=ClearDTC_vDem42.SelectDTC, timeout=0
        sync call OpServerCallSetDTCSuppression_SetDTCSuppression_ControlDTCSuppression43_vDem42: operation=ControlDTCSuppression43_vDem42.SetDTCSuppression, timeout=0
      runnable GetDTCSuppression: can-be-invoked-concurrently=true, symbol=VDem42_GetDTCSuppression
        sync call OpServerCallGetDTCSuppression_SelectDTC_ClearDTC_vDem42: operation=ClearDTC_vDem42.SelectDTC, timeout=0
        sync call OpServerCallGetDTCSuppression_GetDTCSuppression_ControlDTCSuppression43_vDem42: operation=ControlDTCSuppression43_vDem42.GetDTCSuppression, timeout=0
  swc implementation vDem42Implementation: programming-language=C, behavior=vDem42InternalBehavior
    resource consumption vDem42ResourceConsumption
      5 x memory section:
        vDem42_START_SEC_CODE: sw-addrmethod=CODE, symbol=CODE
        vDem42_START_SEC_CONST_UNSPECIFIED: alignment=UNSPECIFIED, sw-addrmethod=CONST, symbol=CONST_UNSPECIFIED
        vDem42_START_SEC_VAR_NOINIT_UNSPECIFIED: alignment=UNSPECIFIED, sw-addrmethod=VAR_NO_INIT, symbol=VAR_NOINIT_UNSPECIFIED
        vDem42_START_SEC_VAR_INIT_UNSPECIFIED: alignment=UNSPECIFIED, sw-addrmethod=VAR_INIT, symbol=VAR_INIT_UNSPECIFIED
        vDem42_START_SEC_VAR_ZERO_INIT_UNSPECIFIED: alignment=UNSPECIFIED, sw-addrmethod=VAR_CLEARED, symbol=VAR_ZERO_INIT_UNSPECIFIED
